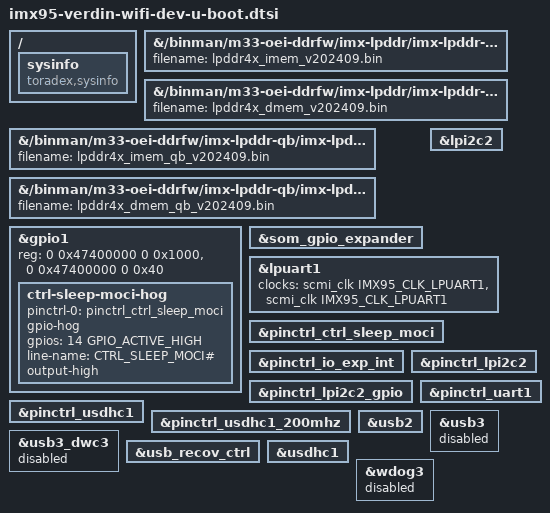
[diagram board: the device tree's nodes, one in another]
// SPDX-License-Identifier: GPL-2.0-or-later OR MIT
/* Copyright (c) Toradex */

#include "imx95-u-boot.dtsi"

/ {
	sysinfo {
		compatible = "toradex,sysinfo";
	};
};

&{/binman/m33-oei-ddrfw/imx-lpddr/imx-lpddr-imem} {
	filename = "lpddr4x_imem_v202409.bin";
};

&{/binman/m33-oei-ddrfw/imx-lpddr/imx-lpddr-dmem} {
	filename = "lpddr4x_dmem_v202409.bin";
};

&{/binman/m33-oei-ddrfw/imx-lpddr-qb/imx-lpddr-imem-qb} {
	filename = "lpddr4x_imem_qb_v202409.bin";
};

&{/binman/m33-oei-ddrfw/imx-lpddr-qb/imx-lpddr-dmem-qb} {
	filename = "lpddr4x_dmem_qb_v202409.bin";
};

&gpio1 {
	reg = <0 0x47400000 0 0x1000>, <0 0x47400000 0 0x40>;
	bootph-pre-ram;

	ctrl-sleep-moci-hog {
		bootph-pre-ram;
		pinctrl-names = "default";
		pinctrl-0 = <&pinctrl_ctrl_sleep_moci>;
		gpio-hog;
		/* Verdin CTRL_SLEEP_MOCI# (SODIMM 256) */
		gpios = <14 GPIO_ACTIVE_HIGH>;
		line-name = "CTRL_SLEEP_MOCI#";
		output-high;
	};
};

&som_gpio_expander {
	bootph-pre-ram;
};

&lpi2c2 {
	bootph-pre-ram;
};

&lpuart1 {
	clocks = <&scmi_clk IMX95_CLK_LPUART1>, <&scmi_clk IMX95_CLK_LPUART1>;
	clock-names = "ipg", "per";
	bootph-pre-ram;
};

&pinctrl_ctrl_sleep_moci {
	bootph-pre-ram;
};

&pinctrl_io_exp_int {
	bootph-pre-ram;
};

&pinctrl_lpi2c2 {
	bootph-pre-ram;
};

&pinctrl_lpi2c2_gpio {
	bootph-pre-ram;
};

&pinctrl_uart1 {
	bootph-pre-ram;
};

&pinctrl_usdhc1 {
	bootph-pre-ram;
};

&pinctrl_usdhc1_200mhz {
	bootph-pre-ram;
};

&som_gpio_expander {
	bootph-pre-ram;
};

&usb2 {
	/delete-property/power-domains;
};

&usb3 {
	status = "disabled";
};

&usb3_dwc3 {
	status = "disabled";
};

&usb_recov_ctrl {
	bootph-pre-ram;
};

&usdhc1 {
	bootph-pre-ram;
};

&wdog3 {
	status = "disabled";
};
